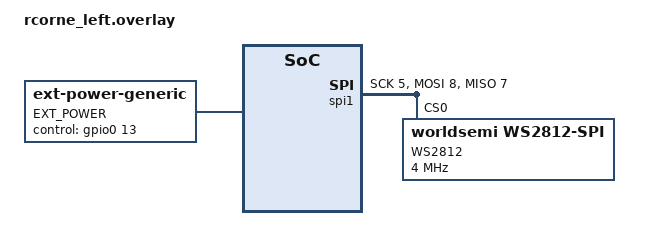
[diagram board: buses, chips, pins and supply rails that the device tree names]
#include "rcorne.dtsi"

&kscan0 {
	col-gpios
		= <&pro_micro 21 GPIO_ACTIVE_HIGH>
		, <&pro_micro 20 GPIO_ACTIVE_HIGH>
		, <&pro_micro 19 GPIO_ACTIVE_HIGH>
		, <&pro_micro 18 GPIO_ACTIVE_HIGH>
		, <&pro_micro 15 GPIO_ACTIVE_HIGH>
		, <&pro_micro 14 GPIO_ACTIVE_HIGH>
		;
};

&spi1 {
	compatible = "nordic,nrf-spim";
	/* Cannot be used together with i2c0. */
	status = "okay";
	mosi-pin = <8>; //gpio 0.08
	// Unused pins, needed for SPI definition, but not used by the ws2812 driver itself.
	sck-pin = <5>;
	miso-pin = <7>;

	led_strip: ws2812@0 {
		compatible = "worldsemi,ws2812-spi";
		label = "WS2812";

		/* SPI */
		reg = <0>; /* ignored, but necessary for SPI bindings */
		spi-max-frequency = <4000000>;

		/* WS2812 */
		chain-length = <6>; /* There are per-key RGB, but the first 6 are underglow */
		spi-one-frame = <0x70>;
		spi-zero-frame = <0x40>;
	};
};

/ {
	chosen {
		zmk,underglow = &led_strip;
	};

	ext-power {
		compatible = "zmk,ext-power-generic";
		label = "EXT_POWER";
		control-gpios = <&gpio0 13 GPIO_ACTIVE_HIGH>;
		init-delay-ms = <50>;
	};

};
